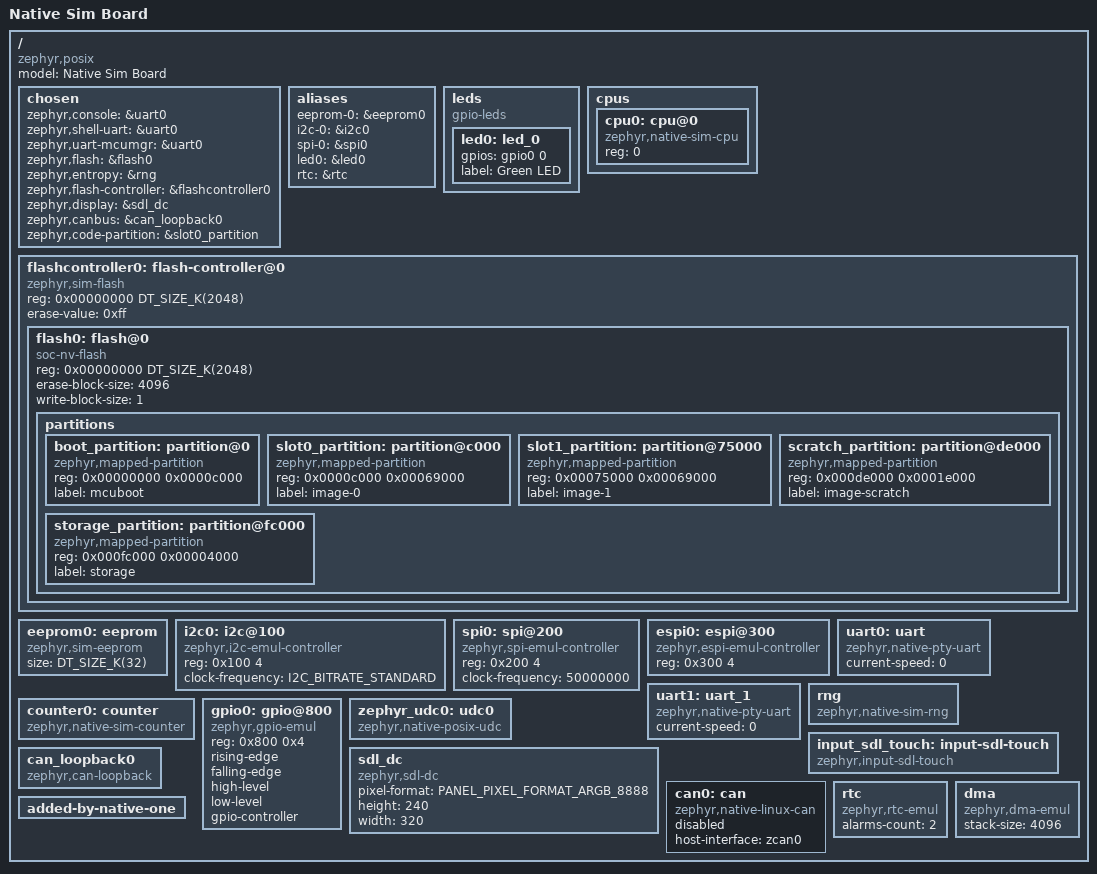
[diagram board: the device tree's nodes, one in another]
/*
 * Copyright (c) 2019 Jan Van Winkel (jan.van_winkel@dxplore.eu)
 *
 * SPDX-License-Identifier: Apache-2.0
 */

/dts-v1/;
#include <posix/posix.dtsi>
#include <zephyr/dt-bindings/adc/adc.h>
#include <zephyr/dt-bindings/display/panel.h>
#include <zephyr/dt-bindings/i2c/i2c.h>
#include <zephyr/dt-bindings/gpio/gpio.h>

/ {
	compatible = "zephyr,posix";
	model = "Native Sim Board";

	chosen {
		zephyr,console = &uart0;
		zephyr,shell-uart = &uart0;
		zephyr,uart-mcumgr = &uart0;
		zephyr,flash = &flash0;
		zephyr,entropy = &rng;
		zephyr,flash-controller = &flashcontroller0;
		zephyr,display = &sdl_dc;
		zephyr,canbus = &can_loopback0;
		zephyr,code-partition = &slot0_partition;
	};

	aliases {
		eeprom-0 = &eeprom0;
		i2c-0 = &i2c0;
		spi-0 = &spi0;
		led0 = &led0;
		rtc = &rtc;
	};

	leds {
		compatible = "gpio-leds";

		led0: led_0 {
			gpios = <&gpio0 0 GPIO_ACTIVE_HIGH>;
			label = "Green LED";
		};
	};

	cpus {
		#address-cells = <1>;
		#size-cells = <0>;

		cpu0: cpu@0 {
			compatible = "zephyr,native-sim-cpu";
			reg = <0>;
		};
	};

	flashcontroller0: flash-controller@0 {
		compatible = "zephyr,sim-flash";
		reg = <0x00000000 DT_SIZE_K(2048)>;
		ranges;

		#address-cells = <1>;
		#size-cells = <1>;
		erase-value = <0xff>;

		flash0: flash@0 {
			compatible = "soc-nv-flash";
			reg = <0x00000000 DT_SIZE_K(2048)>;
			ranges = <0x0 0x00000000 DT_SIZE_K(2048)>;
			erase-block-size = <4096>;
			write-block-size = <1>;
			#address-cells = <1>;
			#size-cells = <1>;
			status = "okay";

			partitions {
				ranges;
				#address-cells = <1>;
				#size-cells = <1>;

				boot_partition: partition@0 {
					compatible = "zephyr,mapped-partition";
					reg = <0x00000000 0x0000c000>;
					label = "mcuboot";
				};

				slot0_partition: partition@c000 {
					compatible = "zephyr,mapped-partition";
					reg = <0x0000c000 0x00069000>;
					label = "image-0";
				};

				slot1_partition: partition@75000 {
					compatible = "zephyr,mapped-partition";
					reg = <0x00075000 0x00069000>;
					label = "image-1";
				};

				scratch_partition: partition@de000 {
					compatible = "zephyr,mapped-partition";
					reg = <0x000de000 0x0001e000>;
					label = "image-scratch";
				};

				storage_partition: partition@fc000 {
					compatible = "zephyr,mapped-partition";
					reg = <0x000fc000 0x00004000>;
					label = "storage";
				};
			};
		};
	};

	eeprom0: eeprom {
		compatible = "zephyr,sim-eeprom";
		size = <DT_SIZE_K(32)>;
		status = "okay";
	};

	i2c0: i2c@100 {
		compatible = "zephyr,i2c-emul-controller";
		reg = <0x100 4>;
		clock-frequency = <I2C_BITRATE_STANDARD>;
		#address-cells = <1>;
		#size-cells = <0>;
		status = "okay";
	};

	spi0: spi@200 {
		compatible = "zephyr,spi-emul-controller";
		reg = <0x200 4>;
		clock-frequency = <50000000>;
		#address-cells = <1>;
		#size-cells = <0>;
		status = "okay";
	};

	espi0: espi@300 {
		compatible = "zephyr,espi-emul-controller";
		reg = <0x300 4>;
		#address-cells = <1>;
		#size-cells = <0>;
		status = "okay";
	};

	uart0: uart {
		compatible = "zephyr,native-pty-uart";
		/* Dummy current-speed entry to comply with serial
		 * DTS binding
		 */
		current-speed = <0>;
		status = "okay";
	};

	uart1: uart_1 {
		compatible = "zephyr,native-pty-uart";
		/* Dummy current-speed entry to comply with serial
		 * DTS binding
		 */
		current-speed = <0>;
		status = "okay";
	};

	rng: rng {
		compatible = "zephyr,native-sim-rng";
		status = "okay";
	};

	counter0: counter {
		compatible = "zephyr,native-sim-counter";
		status = "okay";
	};

	gpio0: gpio@800 {
		compatible = "zephyr,gpio-emul";
		reg = <0x800 0x4>;
		rising-edge;
		falling-edge;
		high-level;
		low-level;
		gpio-controller;
		#gpio-cells = <2>;
		status = "okay";
	};

	zephyr_udc0: udc0 {
		compatible = "zephyr,native-posix-udc";
	};

	sdl_dc: sdl_dc {
		compatible = "zephyr,sdl-dc";
		pixel-format = <PANEL_PIXEL_FORMAT_ARGB_8888>;
		height = <240>;
		width = <320>;
	};

	input_sdl_touch: input-sdl-touch {
		compatible = "zephyr,input-sdl-touch";
	};

	can_loopback0: can_loopback0 {
		compatible = "zephyr,can-loopback";
		status = "okay";
	};

	can0: can {
		compatible = "zephyr,native-linux-can";
		/* adjust zcan0 to desired host interface or create an alternative
		 * name, e.g.: sudo ip link property add dev vcan0 altname zcan0
		 */
		host-interface = "zcan0";
		status = "disabled";
	};

	rtc: rtc {
		compatible = "zephyr,rtc-emul";
		alarms-count = <2>;
		status = "okay";
	};

	dma: dma {
		compatible = "zephyr,dma-emul";
		#dma-cells = <1>;
		stack-size = <4096>;
	};

	added-by-native-one {};
};
